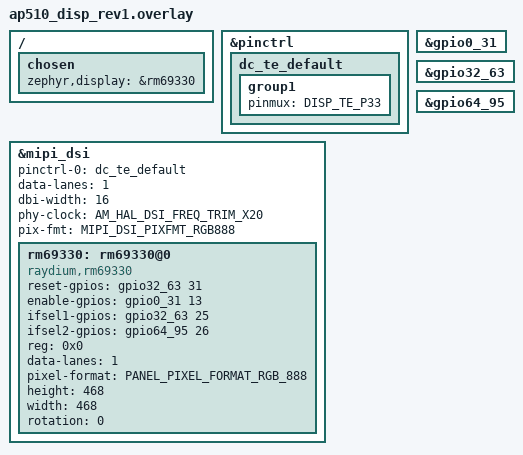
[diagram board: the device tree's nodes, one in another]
/*
 * Copyright (c) 2025 Ambiq Inc.
 *
 * SPDX-License-Identifier: Apache-2.0
 */
 
#include <apollo510/ambiq-apollo510-pinmux.h>
#include <zephyr/dt-bindings/mipi_dsi/mipi_dsi.h>
#include <zephyr/dt-bindings/display/panel.h>

/ {
	chosen {
		zephyr,display = &rm69330;
	};
};

&pinctrl {
    /* Node with pin configuration for default state */
    /omit-if-no-ref/ dc_te_default: dc_te_default {
        group1 {
            /* Mappings: DISP_TE -> GPIO33*/
            pinmux = <DISP_TE_P33>;
        };
    };
};

&mipi_dsi {
	pinctrl-0 = <&dc_te_default>;
    pinctrl-names = "default";
	status = "okay";
	data-lanes = <1>;
	dbi-width = <16>;
	phy-clock = <AM_HAL_DSI_FREQ_TRIM_X20>;
	pix-fmt = <MIPI_DSI_PIXFMT_RGB888>;
	/*disp-te;*/ /*Please select the correct IOX*/

	rm69330: rm69330@0 {
		status = "okay";
		compatible = "raydium,rm69330";
		reset-gpios = <&gpio32_63 31 (GPIO_PULL_UP)>;
		enable-gpios = <&gpio0_31 13 (GPIO_PULL_UP)>;/*unused*/
		ifsel1-gpios = <&gpio32_63 25 (GPIO_PULL_DOWN)>;/*unused*/
		ifsel2-gpios = <&gpio64_95 26 (GPIO_PULL_DOWN)>;/*unused*/
		reg = <0x0>;
		data-lanes = <1>;
		pixel-format = <PANEL_PIXEL_FORMAT_RGB_888>;
		height = <468>;
		width = <468>;
		rotation = <0>;
	};
};

&gpio0_31 {
	status = "okay";
};

&gpio32_63 {
	status = "okay";
};

&gpio64_95 {
	status = "okay";
};
